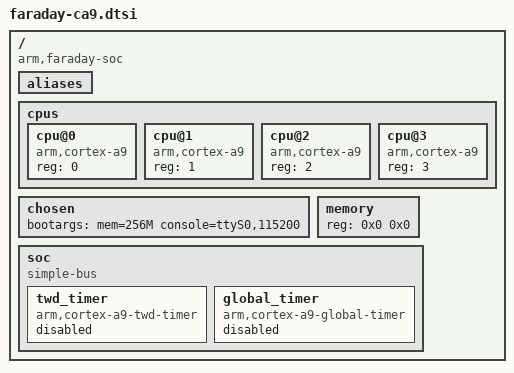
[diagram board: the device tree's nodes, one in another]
/*
 * Copyright (C) 2021 Faraday, Inc. (www.faraday-tech.com)
 *
 * This program is free software; you can redistribute it and/or modify
 * it under the terms of the GNU General Public License version 2 as
 * published by the Free Software Foundation.
 */
 
/dts-v1/;

/ {
	compatible = "arm,faraday-soc";
	#address-cells = <1>;
	#size-cells = <1>;
	
	aliases {};
	
	cpus {
		#address-cells = <1>;
		#size-cells = <0>;
		
		cpu@0 {
			device_type = "cpu";
			compatible = "arm,cortex-a9";
			reg = <0>;
		};
		cpu@1 {
			device_type = "cpu";
			compatible = "arm,cortex-a9";
			reg = <1>;
		};
		cpu@2 {
			device_type = "cpu";
			compatible = "arm,cortex-a9";
			reg = <2>;
		};
		cpu@3 {
			device_type = "cpu";
			compatible = "arm,cortex-a9";
			reg = <3>;
		};
	};
	
	chosen {
		bootargs = "mem=256M console=ttyS0,115200";
	};
	
	memory {
		device_type = "memory";
		reg = <0x0 0x0>;
	};
	
	soc: soc {
		compatible = "simple-bus";
		ranges;
		
		twd_timer: twd_timer {
			compatible = "arm,cortex-a9-twd-timer";
			status = "disable";
		};
		
		global_timer: global_timer {
			compatible = "arm,cortex-a9-global-timer";
			status = "disable";
		};
	};
	
	
};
